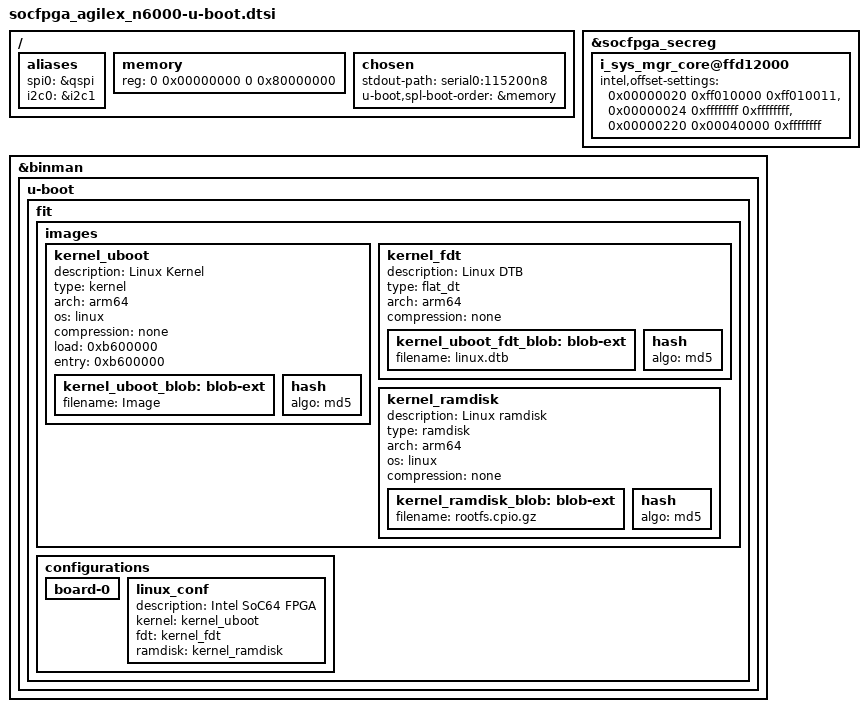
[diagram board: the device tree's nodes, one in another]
// SPDX-License-Identifier: GPL-2.0+
/*
 * U-Boot additions
 *
 * Copyright (C) 2021 Intel Corporation <www.intel.com>
 */

#include "socfpga_agilex-u-boot.dtsi"

/{
	aliases {
		spi0 = &qspi;
		i2c0 = &i2c1;
	};

	memory {
		/* 2GB */
		reg = <0 0x00000000 0 0x80000000>;
	};

	chosen {
		stdout-path = "serial0:115200n8";
		u-boot,spl-boot-order = &memory;
	};
};

&socfpga_secreg {
	i_sys_mgr_core@ffd12000 {
		/delete-property/ intel,offset-settings;
		intel,offset-settings =
			/* Enable non-secure interface to DMA */
			<0x00000020 0xff010000 0xff010011>,
			/* Enable non-secure interface to DMA periph */
			<0x00000024 0xffffffff 0xffffffff>,
			/* Set DDR data rate to 1-Quarter-rate in BOOT_SCRATCH_COLD8 reg */
			<0x00000220 0x00040000 0xffffffff>;
	};
};

&binman {
	/delete-node/ u-boot-script;
	u-boot {
		fit {
			images {
				kernel_uboot {
					description = "Linux Kernel";
					type = "kernel";
					arch = "arm64";
					os = "linux";
					compression = "none";
					load = <0xb600000>;
					entry = <0xb600000>;

					kernel_uboot_blob: blob-ext {
						filename = "Image";
					};
					hash {
						algo = "md5";
					};
				};

				kernel_fdt {
					description = "Linux DTB";
					type = "flat_dt";
					arch = "arm64";
					compression = "none";

					kernel_uboot_fdt_blob: blob-ext {
						filename = "linux.dtb";
					};
					hash {
						algo = "md5";
					};
				};

				kernel_ramdisk {
					description = "Linux ramdisk";
					type = "ramdisk";
					arch = "arm64";
					os = "linux";
					compression = "none";

					kernel_ramdisk_blob: blob-ext {
						filename = "rootfs.cpio.gz";
					};
					hash {
						algo = "md5";
					};
				};
			};

			configurations {
				board-0 {
#if !defined(CONFIG_SPL_ATF)
					/delete-property/ firmware;
#endif
				};

				linux_conf {
					description = "Intel SoC64 FPGA";
					kernel = "kernel_uboot";
					fdt = "kernel_fdt";
					ramdisk = "kernel_ramdisk";
				};
			};
		};
	};

	/delete-node/ kernel;
};
